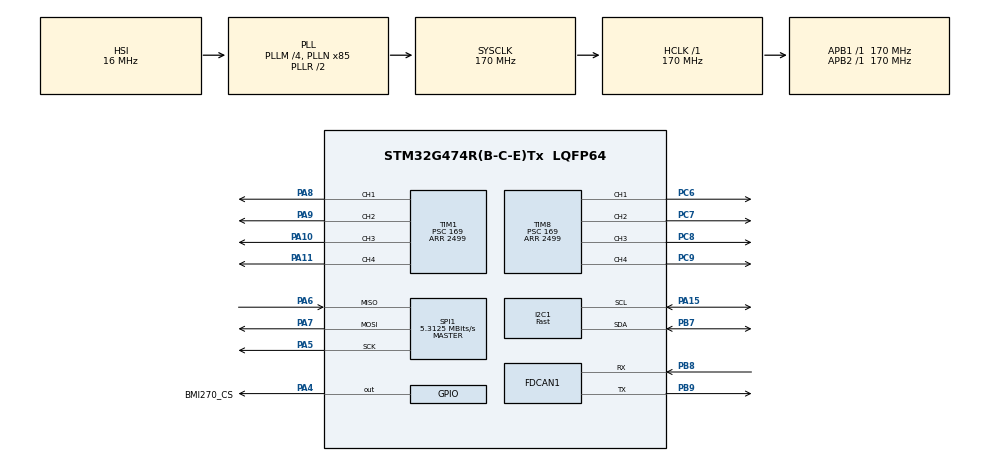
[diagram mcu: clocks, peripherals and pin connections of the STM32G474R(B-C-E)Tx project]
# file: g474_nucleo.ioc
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Dma.Request0=TIM1_CH1
Dma.TIM1_CH1.0.Direction=DMA_MEMORY_TO_PERIPH
Dma.TIM1_CH1.0.EventEnable=DISABLE
Dma.TIM1_CH1.0.Instance=DMA1_Channel1
Dma.TIM1_CH1.0.MemDataAlignment=DMA_MDATAALIGN_HALFWORD
Dma.TIM1_CH1.0.MemInc=DMA_MINC_ENABLE
Dma.TIM1_CH1.0.Mode=DMA_NORMAL
Dma.TIM1_CH1.0.PeriphDataAlignment=DMA_PDATAALIGN_HALFWORD
Dma.TIM1_CH1.0.PeriphInc=DMA_PINC_DISABLE
Dma.TIM1_CH1.0.Polarity=HAL_DMAMUX_REQ_GEN_RISING
Dma.TIM1_CH1.0.Priority=DMA_PRIORITY_HIGH
Dma.TIM1_CH1.0.RequestNumber=1
Dma.TIM1_CH1.0.SignalID=NONE
Dma.TIM1_CH1.0.SyncEnable=DISABLE
Dma.TIM1_CH1.0.SyncPolarity=HAL_DMAMUX_SYNC_NO_EVENT
Dma.TIM1_CH1.0.SyncRequestNumber=1
Dma.TIM1_CH1.0.SyncSignalID=NONE
FDCAN1.CalculateBaudRateNominal=3541666
FDCAN1.CalculateTimeBitNominal=282
FDCAN1.CalculateTimeQuantumNominal=94.11764705882354
I2C1.I2C_Speed_Mode=I2C_Fast
I2C1.Timing=0x40621236
Mcu.Family=STM32G4
Mcu.Name=STM32G474R(B-C-E)Tx
Mcu.Package=LQFP64
NUCLEO-G474RE.BUTTON=0
NUCLEO-G474RE.LD2=false
NUCLEO-G474RE.VCP=false
NVIC.DMA1_Channel1_IRQn=true\:0\:0\:false\:false\:true\:false\:true\:true
NVIC.PriorityGroup=NVIC_PRIORITYGROUP_4
NVIC.TIM6_DAC_IRQn=true\:0\:0\:false\:false\:true\:true\:true\:true
PA10.Signal=S_TIM1_CH3
PA11.Signal=S_TIM1_CH4
PA13.GPIO_Label=T_SWDIO
PA13.Signal=SYS_JTMS-SWDIO
PA14.GPIO_Label=T_SWCLK
PA14.Signal=SYS_JTCK-SWCLK
PA15.Mode=I2C
PA15.Signal=I2C1_SCL
PA4.GPIO_Label=BMI270_CS
PA4.PinState=GPIO_PIN_SET
PA4.Signal=GPIO_Output
PA5.Mode=Full_Duplex_Master
PA5.Signal=SPI1_SCK
PA6.Mode=Full_Duplex_Master
PA6.Signal=SPI1_MISO
PA7.Mode=Full_Duplex_Master
PA7.Signal=SPI1_MOSI
PA8.Signal=S_TIM1_CH1
PA9.Signal=S_TIM1_CH2
PB3.GPIO_Label=T_SWO
PB3.Signal=SYS_JTDO-SWO
PB7.Mode=I2C
PB7.Signal=I2C1_SDA
PB8-BOOT0.Mode=FDCAN_Activate
PB8-BOOT0.Signal=FDCAN1_RX
PB9.Mode=FDCAN_Activate
PB9.Signal=FDCAN1_TX
PC14-OSC32_IN.GPIO_Label=RCC_OSC32_IN
PC14-OSC32_IN.Signal=RCC_OSC32_IN
PC15-OSC32_OUT.GPIO_Label=RCC_OSC32_OUT
PC15-OSC32_OUT.Signal=RCC_OSC32_OUT
PC6.Signal=S_TIM8_CH1
PC7.Signal=S_TIM8_CH2
PC8.Signal=S_TIM8_CH3
PC9.Signal=S_TIM8_CH4
PF0-OSC_IN.GPIO_Label=RCC_OSC_IN
PF0-OSC_IN.Signal=RCC_OSC_IN
PF1-OSC_OUT.GPIO_Label=RCC_OSC_OUT
PF1-OSC_OUT.Signal=RCC_OSC_OUT
ProjectManager.HeapSize=0x200
ProjectManager.StackSize=0x400
ProjectManager.TargetToolchain=CMake
RCC.ADC12Freq_Value=170000000
RCC.ADC345Freq_Value=170000000
RCC.AHBFreq_Value=170000000
RCC.APB1Freq_Value=170000000
RCC.APB1TimFreq_Value=170000000
RCC.APB2Freq_Value=170000000
RCC.APB2TimFreq_Value=170000000
RCC.CortexFreq_Value=170000000
RCC.EXTERNAL_CLOCK_VALUE=12288000
RCC.HCLKFreq_Value=170000000
RCC.HSE_VALUE=24000000
RCC.HSI48_VALUE=48000000
RCC.HSI_VALUE=16000000
RCC.LSE_VALUE=32768
RCC.PLLM=RCC_PLLM_DIV4
RCC.PLLN=85
RCC.RTCClockSelection=RCC_RTCCLKSOURCE_LSE
RCC.SYSCLKFreq_VALUE=170000000
RCC.SYSCLKSource=RCC_SYSCLKSOURCE_PLLCLK
RCC.USBFreq_Value=170000000
RCC.VCOOutputFreq_Value=340000000
SH.S_TIM1_CH1.0=TIM1_CH1,PWM Generation1 CH1
SH.S_TIM1_CH2.0=TIM1_CH2,PWM Generation2 CH2
SH.S_TIM1_CH3.0=TIM1_CH3,PWM Generation3 CH3
SH.S_TIM1_CH4.0=TIM1_CH4,PWM Generation4 CH4
SH.S_TIM8_CH1.0=TIM8_CH1,PWM Generation1 CH1
SH.S_TIM8_CH2.0=TIM8_CH2,PWM Generation2 CH2
SH.S_TIM8_CH3.0=TIM8_CH3,PWM Generation3 CH3
SH.S_TIM8_CH4.0=TIM8_CH4,PWM Generation4 CH4
SPI1.BaudRatePrescaler=SPI_BAUDRATEPRESCALER_32
SPI1.CalculateBaudRate=5.3125 MBits/s
SPI1.DataSize=SPI_DATASIZE_8BIT
SPI1.Direction=SPI_DIRECTION_2LINES
SPI1.Mode=SPI_MODE_MASTER
SPI1.VirtualType=VM_MASTER
TIM1.AutoReloadPreload=TIM_AUTORELOAD_PRELOAD_ENABLE
TIM1.Channel-PWM\ Generation1\ CH1=TIM_CHANNEL_1
TIM1.Channel-PWM\ Generation2\ CH2=TIM_CHANNEL_2
TIM1.Channel-PWM\ Generation3\ CH3=TIM_CHANNEL_3
TIM1.Channel-PWM\ Generation4\ CH4=TIM_CHANNEL_4
TIM1.PeriodNoDither=2499
TIM1.Prescaler=169
TIM1.PulseNoDither_1=1500
TIM1.PulseNoDither_2=1500
TIM1.PulseNoDither_3=1500
TIM1.PulseNoDither_4=1500
TIM6.AutoReloadPreload=TIM_AUTORELOAD_PRELOAD_ENABLE
TIM6.PeriodNoDither=999
TIM6.Prescaler=169
TIM8.AutoReloadPreload=TIM_AUTORELOAD_PRELOAD_ENABLE
TIM8.Channel-PWM\ Generation1\ CH1=TIM_CHANNEL_1
TIM8.Channel-PWM\ Generation2\ CH2=TIM_CHANNEL_2
TIM8.Channel-PWM\ Generation3\ CH3=TIM_CHANNEL_3
TIM8.Channel-PWM\ Generation4\ CH4=TIM_CHANNEL_4
TIM8.PeriodNoDither=2499
TIM8.Prescaler=169
TIM8.PulseNoDither_1=1500
TIM8.PulseNoDither_2=1500
TIM8.PulseNoDither_3=1500
TIM8.PulseNoDither_4=1500
VP_NUCLEO-G474RE_VS_BSP_COMMON.Mode=COMMON
VP_SYS_VS_DBSignals.Mode=DisableDeadBatterySignals
VP_TIM1_VS_ClockSourceINT.Mode=Internal
VP_TIM6_VS_ClockSourceINT.Mode=Enable_Timer
VP_TIM8_VS_ClockSourceINT.Mode=Internal
board=NUCLEO-G474RE

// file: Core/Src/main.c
/* USER CODE BEGIN Header */
/**
 ******************************************************************************
 * @file           : main.c
 * @brief          : Main program body
 ******************************************************************************
 * @attention
 *
 * Copyright (c) 2026 STMicroelectronics.
 * All rights reserved.
 *
 * This software is licensed under terms that can be found in the LICENSE file
 * in the root directory of this software component.
 * If no LICENSE file comes with this software, it is provided AS-IS.
 *
 ******************************************************************************
 */
/* USER CODE END Header */
#include "main.h"

/* USER CODE BEGIN Includes */
#include "app.h"
#include "bsp.h"

/* USER CODE END Includes */

FDCAN_HandleTypeDef hfdcan1;

I2C_HandleTypeDef hi2c1;

SPI_HandleTypeDef hspi1;

TIM_HandleTypeDef htim1;
TIM_HandleTypeDef htim6;
TIM_HandleTypeDef htim8;

void SystemClock_Config(void);
static void MX_GPIO_Init(void);
static void MX_FDCAN1_Init(void);
static void MX_I2C1_Init(void);
static void MX_SPI1_Init(void);
static void MX_TIM1_Init(void);
static void MX_TIM6_Init(void);
static void MX_TIM8_Init(void);

int main(void) {

    /* MCU Configuration--------------------------------------------------------*/

    /* Reset of all peripherals, Initializes the Flash interface and the Systick. */
    HAL_Init();

    /* Configure the system clock */
    SystemClock_Config();

    /* Initialize all configured peripherals */
    MX_GPIO_Init();
    MX_FDCAN1_Init();
    MX_I2C1_Init();
    MX_SPI1_Init();
    MX_TIM1_Init();
    MX_TIM6_Init();
    MX_TIM8_Init();
    /* USER CODE BEGIN 2 */
    /* Hand over execution to Application Layer (Src/app.c).
     * CubeMX code generation preserves this call, while all
     * application logic, state machines, and telemetry stay safe in app.c */
    app_main();
    /* USER CODE END 2 */

    /* Infinite loop */
    while (1) {

    }
}

void SystemClock_Config(void) {
    RCC_OscInitTypeDef RCC_OscInitStruct = {0};
    RCC_ClkInitTypeDef RCC_ClkInitStruct = {0};

    /** Configure the main internal regulator output voltage
     */
    HAL_PWREx_ControlVoltageScaling(PWR_REGULATOR_VOLTAGE_SCALE1_BOOST);

    /** Initializes the RCC Oscillators according to the specified parameters
     * in the RCC_OscInitTypeDef structure.
     */
    RCC_OscInitStruct.OscillatorType = RCC_OSCILLATORTYPE_HSI;
    RCC_OscInitStruct.HSIState = RCC_HSI_ON;
    RCC_OscInitStruct.HSICalibrationValue = RCC_HSICALIBRATION_DEFAULT;
    RCC_OscInitStruct.PLL.PLLState = RCC_PLL_ON;
    RCC_OscInitStruct.PLL.PLLSource = RCC_PLLSOURCE_HSI;
    RCC_OscInitStruct.PLL.PLLM = RCC_PLLM_DIV4;
    RCC_OscInitStruct.PLL.PLLN = 85;
    RCC_OscInitStruct.PLL.PLLP = RCC_PLLP_DIV2;
    RCC_OscInitStruct.PLL.PLLQ = RCC_PLLQ_DIV2;
    RCC_OscInitStruct.PLL.PLLR = RCC_PLLR_DIV2;
    if (HAL_RCC_OscConfig(&RCC_OscInitStruct) != HAL_OK) {
        Error_Handler();
    }

    /** Initializes the CPU, AHB and APB buses clocks
     */
    RCC_ClkInitStruct.ClockType = RCC_CLOCKTYPE_HCLK | RCC_CLOCKTYPE_SYSCLK | RCC_CLOCKTYPE_PCLK1 | RCC_CLOCKTYPE_PCLK2;
    RCC_ClkInitStruct.SYSCLKSource = RCC_SYSCLKSOURCE_PLLCLK;
    RCC_ClkInitStruct.AHBCLKDivider = RCC_SYSCLK_DIV1;
    RCC_ClkInitStruct.APB1CLKDivider = RCC_HCLK_DIV1;
    RCC_ClkInitStruct.APB2CLKDivider = RCC_HCLK_DIV1;

    if (HAL_RCC_ClockConfig(&RCC_ClkInitStruct, FLASH_LATENCY_4) != HAL_OK) {
        Error_Handler();
    }
}

static void MX_FDCAN1_Init(void) {

    hfdcan1.Instance = FDCAN1;
    hfdcan1.Init.ClockDivider = FDCAN_CLOCK_DIV1;
    hfdcan1.Init.FrameFormat = FDCAN_FRAME_FD_BRS;
    hfdcan1.Init.Mode = FDCAN_MODE_NORMAL;
    hfdcan1.Init.AutoRetransmission = ENABLE;
    hfdcan1.Init.TransmitPause = DISABLE;
    hfdcan1.Init.ProtocolException = DISABLE;
    hfdcan1.Init.NominalPrescaler = 10;
    hfdcan1.Init.NominalSyncJumpWidth = 3;
    hfdcan1.Init.NominalTimeSeg1 = 13;
    hfdcan1.Init.NominalTimeSeg2 = 3;
    hfdcan1.Init.DataPrescaler = 2;
    hfdcan1.Init.DataSyncJumpWidth = 4;
    hfdcan1.Init.DataTimeSeg1 = 12;
    hfdcan1.Init.DataTimeSeg2 = 4;
    hfdcan1.Init.StdFiltersNbr = 0;
    hfdcan1.Init.ExtFiltersNbr = 0;
    hfdcan1.Init.TxFifoQueueMode = FDCAN_TX_FIFO_OPERATION;
    if (HAL_FDCAN_Init(&hfdcan1) != HAL_OK) {
        Error_Handler();
    }
}

static void MX_I2C1_Init(void) {

    hi2c1.Instance = I2C1;
    hi2c1.Init.Timing = 0x40621236;
    hi2c1.Init.OwnAddress1 = 0;
    hi2c1.Init.AddressingMode = I2C_ADDRESSINGMODE_7BIT;
    hi2c1.Init.DualAddressMode = I2C_DUALADDRESS_DISABLE;
    hi2c1.Init.OwnAddress2 = 0;
    hi2c1.Init.OwnAddress2Masks = I2C_OA2_NOMASK;
    hi2c1.Init.GeneralCallMode = I2C_GENERALCALL_DISABLE;
    hi2c1.Init.NoStretchMode = I2C_NOSTRETCH_DISABLE;
    if (HAL_I2C_Init(&hi2c1) != HAL_OK) {
        Error_Handler();
    }

    /** Configure Analogue filter
     */
    if (HAL_I2CEx_ConfigAnalogFilter(&hi2c1, I2C_ANALOGFILTER_ENABLE) != HAL_OK) {
        Error_Handler();
    }

    /** Configure Digital filter
     */
    if (HAL_I2CEx_ConfigDigitalFilter(&hi2c1, 0) != HAL_OK) {
        Error_Handler();
    }
}

static void MX_SPI1_Init(void) {

    /* SPI1 parameter configuration*/
    hspi1.Instance = SPI1;
    hspi1.Init.Mode = SPI_MODE_MASTER;
    hspi1.Init.Direction = SPI_DIRECTION_2LINES;
    hspi1.Init.DataSize = SPI_DATASIZE_8BIT;
    hspi1.Init.CLKPolarity = SPI_POLARITY_LOW;
    hspi1.Init.CLKPhase = SPI_PHASE_1EDGE;
    hspi1.Init.NSS = SPI_NSS_SOFT;
    hspi1.Init.BaudRatePrescaler = SPI_BAUDRATEPRESCALER_32;
    hspi1.Init.FirstBit = SPI_FIRSTBIT_MSB;
    hspi1.Init.TIMode = SPI_TIMODE_DISABLE;
    hspi1.Init.CRCCalculation = SPI_CRCCALCULATION_DISABLE;
    hspi1.Init.CRCPolynomial = 7;
    hspi1.Init.CRCLength = SPI_CRC_LENGTH_DATASIZE;
    hspi1.Init.NSSPMode = SPI_NSS_PULSE_ENABLE;
    if (HAL_SPI_Init(&hspi1) != HAL_OK) {
        Error_Handler();
    }
}

static void MX_TIM1_Init(void) {

    TIM_ClockConfigTypeDef sClockSourceConfig = {0};
    TIM_MasterConfigTypeDef sMasterConfig = {0};
    TIM_OC_InitTypeDef sConfigOC = {0};
    TIM_BreakDeadTimeConfigTypeDef sBreakDeadTimeConfig = {0};

    htim1.Instance = TIM1;
    htim1.Init.Prescaler = 169;
    htim1.Init.CounterMode = TIM_COUNTERMODE_UP;
    htim1.Init.Period = 2499;
    htim1.Init.ClockDivision = TIM_CLOCKDIVISION_DIV1;
    htim1.Init.RepetitionCounter = 0;
    htim1.Init.AutoReloadPreload = TIM_AUTORELOAD_PRELOAD_ENABLE;
    if (HAL_TIM_Base_Init(&htim1) != HAL_OK) {
        Error_Handler();
    }
    sClockSourceConfig.ClockSource = TIM_CLOCKSOURCE_INTERNAL;
    if (HAL_TIM_ConfigClockSource(&htim1, &sClockSourceConfig) != HAL_OK) {
        Error_Handler();
    }
    if (HAL_TIM_PWM_Init(&htim1) != HAL_OK) {
        Error_Handler();
    }
    sMasterConfig.MasterOutputTrigger = TIM_TRGO_RESET;
    sMasterConfig.MasterOutputTrigger2 = TIM_TRGO2_RESET;
    sMasterConfig.MasterSlaveMode = TIM_MASTERSLAVEMODE_DISABLE;
    if (HAL_TIMEx_MasterConfigSynchronization(&htim1, &sMasterConfig) != HAL_OK) {
        Error_Handler();
    }
    sConfigOC.OCMode = TIM_OCMODE_PWM1;
    sConfigOC.Pulse = 1500;
    sConfigOC.OCPolarity = TIM_OCPOLARITY_HIGH;
    sConfigOC.OCNPolarity = TIM_OCNPOLARITY_HIGH;
    sConfigOC.OCFastMode = TIM_OCFAST_DISABLE;
    sConfigOC.OCIdleState = TIM_OCIDLESTATE_RESET;
    sConfigOC.OCNIdleState = TIM_OCNIDLESTATE_RESET;
    if (HAL_TIM_PWM_ConfigChannel(&htim1, &sConfigOC, TIM_CHANNEL_1) != HAL_OK) {
        Error_Handler();
    }
    if (HAL_TIM_PWM_ConfigChannel(&htim1, &sConfigOC, TIM_CHANNEL_2) != HAL_OK) {
        Error_Handler();
    }
    if (HAL_TIM_PWM_ConfigChannel(&htim1, &sConfigOC, TIM_CHANNEL_3) != HAL_OK) {
        Error_Handler();
    }
    if (HAL_TIM_PWM_ConfigChannel(&htim1, &sConfigOC, TIM_CHANNEL_4) != HAL_OK) {
        Error_Handler();
    }
    sBreakDeadTimeConfig.OffStateRunMode = TIM_OSSR_DISABLE;
    sBreakDeadTimeConfig.OffStateIDLEMode = TIM_OSSI_DISABLE;
    sBreakDeadTimeConfig.LockLevel = TIM_LOCKLEVEL_OFF;
    sBreakDeadTimeConfig.DeadTime = 0;
    sBreakDeadTimeConfig.BreakState = TIM_BREAK_DISABLE;
    sBreakDeadTimeConfig.BreakPolarity = TIM_BREAKPOLARITY_HIGH;
    sBreakDeadTimeConfig.BreakFilter = 0;
    sBreakDeadTimeConfig.BreakAFMode = TIM_BREAK_AFMODE_INPUT;
    sBreakDeadTimeConfig.Break2State = TIM_BREAK2_DISABLE;
    sBreakDeadTimeConfig.Break2Polarity = TIM_BREAK2POLARITY_HIGH;
    sBreakDeadTimeConfig.Break2Filter = 0;
    sBreakDeadTimeConfig.Break2AFMode = TIM_BREAK_AFMODE_INPUT;
    sBreakDeadTimeConfig.AutomaticOutput = TIM_AUTOMATICOUTPUT_DISABLE;
    if (HAL_TIMEx_ConfigBreakDeadTime(&htim1, &sBreakDeadTimeConfig) != HAL_OK) {
        Error_Handler();
    }
    HAL_TIM_MspPostInit(&htim1);
}

static void MX_TIM6_Init(void) {

    TIM_MasterConfigTypeDef sMasterConfig = {0};

    htim6.Instance = TIM6;
    htim6.Init.Prescaler = 169;
    htim6.Init.CounterMode = TIM_COUNTERMODE_UP;
    htim6.Init.Period = 999;
    htim6.Init.AutoReloadPreload = TIM_AUTORELOAD_PRELOAD_ENABLE;
    if (HAL_TIM_Base_Init(&htim6) != HAL_OK) {
        Error_Handler();
    }
    sMasterConfig.MasterOutputTrigger = TIM_TRGO_RESET;
    sMasterConfig.MasterSlaveMode = TIM_MASTERSLAVEMODE_DISABLE;
    if (HAL_TIMEx_MasterConfigSynchronization(&htim6, &sMasterConfig) != HAL_OK) {
        Error_Handler();
    }
}

static void MX_TIM8_Init(void) {

    TIM_ClockConfigTypeDef sClockSourceConfig = {0};
    TIM_MasterConfigTypeDef sMasterConfig = {0};
    TIM_OC_InitTypeDef sConfigOC = {0};
    TIM_BreakDeadTimeConfigTypeDef sBreakDeadTimeConfig = {0};

    htim8.Instance = TIM8;
    htim8.Init.Prescaler = 169;
    htim8.Init.CounterMode = TIM_COUNTERMODE_UP;
    htim8.Init.Period = 2499;
    htim8.Init.ClockDivision = TIM_CLOCKDIVISION_DIV1;
    htim8.Init.RepetitionCounter = 0;
    htim8.Init.AutoReloadPreload = TIM_AUTORELOAD_PRELOAD_ENABLE;
    if (HAL_TIM_Base_Init(&htim8) != HAL_OK) {
        Error_Handler();
    }
    sClockSourceConfig.ClockSource = TIM_CLOCKSOURCE_INTERNAL;
    if (HAL_TIM_ConfigClockSource(&htim8, &sClockSourceConfig) != HAL_OK) {
        Error_Handler();
    }
    if (HAL_TIM_PWM_Init(&htim8) != HAL_OK) {
        Error_Handler();
    }
    sMasterConfig.MasterOutputTrigger = TIM_TRGO_RESET;
    sMasterConfig.MasterOutputTrigger2 = TIM_TRGO2_RESET;
    sMasterConfig.MasterSlaveMode = TIM_MASTERSLAVEMODE_DISABLE;
    if (HAL_TIMEx_MasterConfigSynchronization(&htim8, &sMasterConfig) != HAL_OK) {
        Error_Handler();
    }
    sConfigOC.OCMode = TIM_OCMODE_PWM1;
    sConfigOC.Pulse = 1500;
    sConfigOC.OCPolarity = TIM_OCPOLARITY_HIGH;
    sConfigOC.OCNPolarity = TIM_OCNPOLARITY_HIGH;
    sConfigOC.OCFastMode = TIM_OCFAST_DISABLE;
    sConfigOC.OCIdleState = TIM_OCIDLESTATE_RESET;
    sConfigOC.OCNIdleState = TIM_OCNIDLESTATE_RESET;
    if (HAL_TIM_PWM_ConfigChannel(&htim8, &sConfigOC, TIM_CHANNEL_1) != HAL_OK) {
        Error_Handler();
    }
    if (HAL_TIM_PWM_ConfigChannel(&htim8, &sConfigOC, TIM_CHANNEL_2) != HAL_OK) {
        Error_Handler();
    }
    if (HAL_TIM_PWM_ConfigChannel(&htim8, &sConfigOC, TIM_CHANNEL_3) != HAL_OK) {
        Error_Handler();
    }
    if (HAL_TIM_PWM_ConfigChannel(&htim8, &sConfigOC, TIM_CHANNEL_4) != HAL_OK) {
        Error_Handler();
    }
    sBreakDeadTimeConfig.OffStateRunMode = TIM_OSSR_DISABLE;
    sBreakDeadTimeConfig.OffStateIDLEMode = TIM_OSSI_DISABLE;
    sBreakDeadTimeConfig.LockLevel = TIM_LOCKLEVEL_OFF;
    sBreakDeadTimeConfig.DeadTime = 0;
    sBreakDeadTimeConfig.BreakState = TIM_BREAK_DISABLE;
    sBreakDeadTimeConfig.BreakPolarity = TIM_BREAKPOLARITY_HIGH;
    sBreakDeadTimeConfig.BreakFilter = 0;
    sBreakDeadTimeConfig.BreakAFMode = TIM_BREAK_AFMODE_INPUT;
    sBreakDeadTimeConfig.Break2State = TIM_BREAK2_DISABLE;
    sBreakDeadTimeConfig.Break2Polarity = TIM_BREAK2POLARITY_HIGH;
    sBreakDeadTimeConfig.Break2Filter = 0;
    sBreakDeadTimeConfig.Break2AFMode = TIM_BREAK_AFMODE_INPUT;
    sBreakDeadTimeConfig.AutomaticOutput = TIM_AUTOMATICOUTPUT_DISABLE;
    if (HAL_TIMEx_ConfigBreakDeadTime(&htim8, &sBreakDeadTimeConfig) != HAL_OK) {
        Error_Handler();
    }
    HAL_TIM_MspPostInit(&htim8);
}

static void MX_GPIO_Init(void) {
    GPIO_InitTypeDef GPIO_InitStruct = {0};

    /* GPIO Ports Clock Enable */
    __HAL_RCC_GPIOC_CLK_ENABLE();
    __HAL_RCC_GPIOF_CLK_ENABLE();
    __HAL_RCC_GPIOA_CLK_ENABLE();
    __HAL_RCC_GPIOB_CLK_ENABLE();

    /*Configure GPIO pin Output Level */
    HAL_GPIO_WritePin(BMI270_CS_GPIO_Port, BMI270_CS_Pin, GPIO_PIN_SET);

    /*Configure GPIO pin : BMI270_CS_Pin */
    GPIO_InitStruct.Pin = BMI270_CS_Pin;
    GPIO_InitStruct.Mode = GPIO_MODE_OUTPUT_PP;
    GPIO_InitStruct.Pull = GPIO_NOPULL;
    GPIO_InitStruct.Speed = GPIO_SPEED_FREQ_LOW;
    HAL_GPIO_Init(BMI270_CS_GPIO_Port, &GPIO_InitStruct);

}

void Error_Handler(void) {
    /* USER CODE BEGIN Error_Handler_Debug */
#if defined(TIM1) && defined(TIM_BDTR_MOE)
    TIM1->BDTR &= ~TIM_BDTR_MOE;
#endif
#if defined(TIM8) && defined(TIM_BDTR_MOE)
    TIM8->BDTR &= ~TIM_BDTR_MOE;
#endif
    bsp_emergency_brake_trip();
    __disable_irq();
    while (1) {
    }
    /* USER CODE END Error_Handler_Debug */
}
